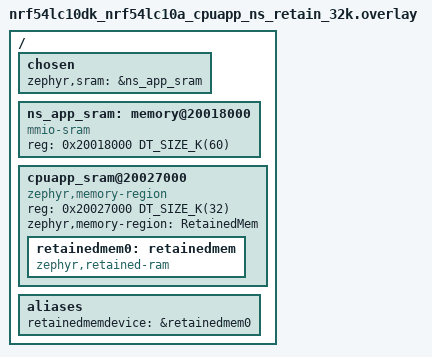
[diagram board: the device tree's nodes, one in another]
/ {
	chosen {
		zephyr,sram = &ns_app_sram;
	};

	ns_app_sram: memory@20018000 {
		compatible = "mmio-sram";
		reg = <0x20018000 DT_SIZE_K(60)>;
	};

	cpuapp_sram@20027000 {
		compatible = "zephyr,memory-region", "mmio-sram";
		reg = <0x20027000 DT_SIZE_K(32)>;
		zephyr,memory-region = "RetainedMem";
		status = "okay";

		retainedmem0: retainedmem {
			compatible = "zephyr,retained-ram";
			status = "okay";
		};
	};

	aliases {
		retainedmemdevice = &retainedmem0;
	};
};
